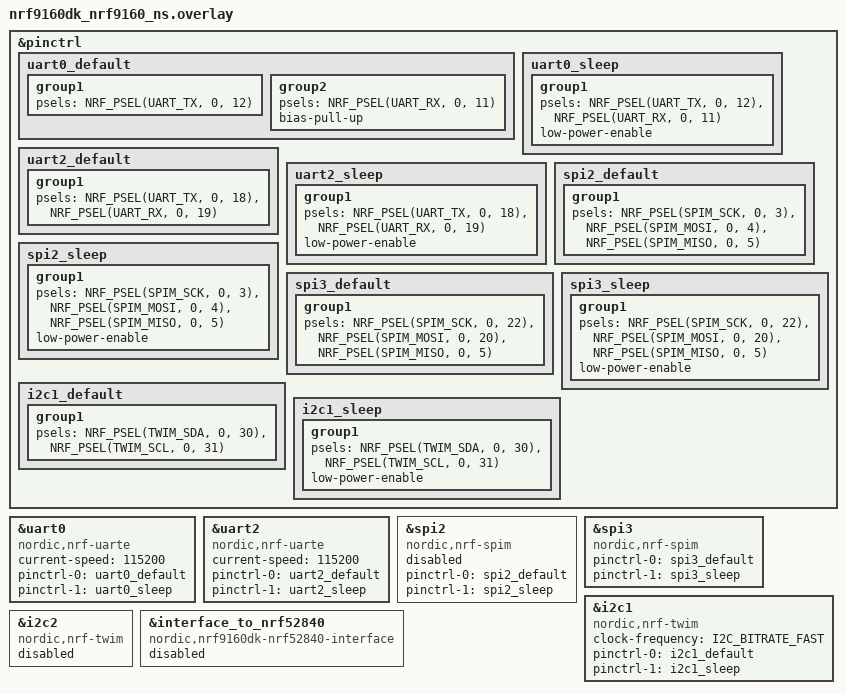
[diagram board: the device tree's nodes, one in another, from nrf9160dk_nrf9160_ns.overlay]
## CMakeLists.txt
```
#
# Copyright (c) 2019 Nordic Semiconductor ASA
#
# SPDX-License-Identifier: LicenseRef-BSD-5-Clause-Nordic
#

cmake_minimum_required(VERSION 3.20.0)

find_package(Zephyr REQUIRED HINTS $ENV{ZEPHYR_BASE})
project(E2)

target_sources(app PRIVATE src/main.c)
target_include_directories(app PRIVATE $ENV{ZEPHYR_BASE}/subsys/fs/nvs)

add_subdirectory(src/datetime)
add_subdirectory(src/font)
add_subdirectory(src/image)
add_subdirectory(src/lcd)
add_subdirectory(src/key)
add_subdirectory(src/settings)
add_subdirectory(src/inner_flash)
add_subdirectory(src/external_flash)
add_subdirectory(src/uart_ble)
add_subdirectory(src/gps)
add_subdirectory(src/nb)
add_subdirectory(src/screen)
add_subdirectory(src/pmu)
add_subdirectory(src/sos)
add_subdirectory(src/codetrans)
add_subdirectory(src/ucs2)
add_subdirectory(src/communicate)
add_subdirectory(src/logger)
#add_subdirectory(src/cryptoauthentication)

add_subdirectory_ifdef(CONFIG_ALARM_SUPPORT src/alarm)
add_subdirectory_ifdef(CONFIG_ANIMATION_SUPPORT src/animation)
add_subdirectory_ifdef(CONFIG_TOUCH_SUPPORT src/tp)
add_subdirectory_ifdef(CONFIG_IMU_SUPPORT src/imu)
add_subdirectory_ifdef(CONFIG_PPG_SUPPORT src/ppg)
add_subdirectory_ifdef(CONFIG_AUDIO_SUPPORT src/audio)
add_subdirectory_ifdef(CONFIG_TEMP_SUPPORT src/temperature)
add_subdirectory_ifdef(CONFIG_CRC_SUPPORT src/crc_check)
add_subdirectory_ifdef(CONFIG_SYNC_SUPPORT src/sync)
add_subdirectory_ifdef(CONFIG_WIFI_SUPPORT src/wifi)
add_subdirectory_ifdef(CONFIG_WATCHDOG src/watchdog)
add_subdirectory_ifdef(CONFIG_FOTA_DOWNLOAD src/fota)
add_subdirectory_ifdef(CONFIG_DATA_DOWNLOAD_SUPPORT src/data_download)
add_subdirectory_ifdef(CONFIG_BARCODE_SUPPORT src/barcode)
add_subdirectory_ifdef(CONFIG_QRCODE_SUPPORT src/qrcode)
add_subdirectory_ifdef(CONFIG_FACTORY_TEST_SUPPORT src/factory_test)
```

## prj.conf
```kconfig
#
# Copyright (c) 2019 Nordic Semiconductor ASA
#
# SPDX-License-Identifier: LicenseRef-BSD-5-Clause-Nordic
#
# General config
CONFIG_NEWLIB_LIBC=y
CONFIG_NEWLIB_LIBC_FLOAT_PRINTF=y
CONFIG_ASSERT=y
CONFIG_REBOOT=y
CONFIG_GPIO=y
CONFIG_TRUSTED_EXECUTION_NONSECURE=y

# Log
CONFIG_LOG=n
CONFIG_USE_SEGGER_RTT=y
CONFIG_LOG_BACKEND_RTT=y
CONFIG_LOG_BACKEND_UART=n
CONFIG_LOG_DEFAULT_LEVEL=4
CONFIG_LOG_MODE_OVERFLOW=y
CONFIG_LOG_BACKEND_RTT_MODE_DROP=y
CONFIG_LOG_BACKEND_SHOW_COLOR=n
CONFIG_LOG_BACKEND_FORMAT_TIMESTAMP=n

# TFM config
#CONFIG_BUILD_WITH_TFM=y
#CONFIG_TFM_PROFILE_TYPE_NOT_SET=y
#CONFIG_TFM_PROFILE_TYPE_MINIMAL=y
#CONFIG_TFM_IPC=n

# PinCtrl
CONFIG_PINCTRL=y
CONFIG_PINCTRL_NRF=y

# watch dog
CONFIG_WATCHDOG=y
CONFIG_WATCHDOG_TIMEOUT_MSEC=10000

# Modem info
CONFIG_MODEM_INFO=y

# Modem library
CONFIG_NRF_MODEM_LIB=y
CONFIG_NRF_MODEM_LIB_SYS_INIT=n

# NVS
CONFIG_FLASH=y
CONFIG_FLASH_PAGE_LAYOUT=y
CONFIG_NVS=y
CONFIG_NVS_LOG_LEVEL_DBG=y
CONFIG_MPU_ALLOW_FLASH_WRITE=y

# GPS
CONFIG_GPS_SUPPORT=y
# Enable to use an external GNSS antenna
CONFIG_GNSS_SAMPLE_ANTENNA_EXTERNAL=y
# Enable to use nRF Cloud A-GPS
CONFIG_GNSS_SAMPLE_ASSISTANCE_NRF_CLOUD=n
# Secure User-Plane Location (SUPL) client library (https://developer.nordicsemi.com/nRF_Connect_SDK/doc/latest/nrf/libraries/others/supl_os_client.html)
CONFIG_GNSS_SAMPLE_ASSISTANCE_SUPL=y

# Console
CONFIG_CONSOLE_SUBSYS=n
CONFIG_CONSOLE_HANDLER=n
CONFIG_CONSOLE_GETCHAR=n
CONFIG_CONSOLE=y
CONFIG_RTT_CONSOLE=y
CONFIG_UART_CONSOLE=n

# Network
CONFIG_NETWORKING=y
CONFIG_NET_NATIVE=n
CONFIG_NET_SOCKETS_OFFLOAD=y
CONFIG_NET_SOCKETS=y
CONFIG_NET_SOCKETS_POSIX_NAMES=y

# Socket
CONFIG_POSIX_MAX_FDS=15
CONFIG_NET_SOCKETS_TLS_MAX_CONTEXTS=5

# LTE link control
CONFIG_LTE_LINK_CONTROL=y
CONFIG_LTE_AUTO_INIT_AND_CONNECT=n
CONFIG_LTE_NETWORK_USE_FALLBACK=n
CONFIG_LTE_NETWORK_TIMEOUT=120
CONFIG_LTE_NETWORK_MODE_LTE_M_GPS=n
CONFIG_LTE_NETWORK_MODE_NBIOT_GPS=y

# PSM
CONFIG_MODEM_AUTO_REQUEST_POWER_SAVING_FEATURES=y
# Set Periodic-TAU timer to 70 mins and Active-Time to 10 seconds.
CONFIG_LTE_PSM_REQ_RPTAU="00000111"
CONFIG_LTE_PSM_REQ_RAT="00000101"

# MQTT
CONFIG_MQTT_LIB=y
CONFIG_MQTT_LIB_TLS=n
CONFIG_MQTT_KEEPALIVE=60
CONFIG_MQTT_PUB_TOPIC="device/e2/pushdata"
CONFIG_MQTT_LOG_PUB_TOPIC="device/e2/pushlog"
CONFIG_MQTT_SUB_TOPIC="device/e2/"
CONFIG_MQTT_CLIENT_ID="my-client-id"
CONFIG_MQTT_USER_NAME="admin123"
CONFIG_MQTT_PASSWORD="admin123"
CONFIG_MQTT_DOMESTIC_BROKER_HOSTNAME="device.audarhealth.cn"
CONFIG_MQTT_DOMESTIC_BROKER_PORT=1883
CONFIG_MQTT_FOREIGN_BROKER_HOSTNAME="device.audarhealth.com"
CONFIG_MQTT_FOREIGN_BROKER_PORT=1883
CONFIG_MQTT_MESSAGE_BUFFER_SIZE=4096
CONFIG_MQTT_PAYLOAD_BUFFER_SIZE=4096

# Library for buttons and LEDs
CONFIG_DK_LIBRARY=y

# Heap and stacks
CONFIG_HEAP_MEM_POOL_SIZE=16384
CONFIG_MAIN_STACK_SIZE=8192
CONFIG_SYSTEM_WORKQUEUE_STACK_SIZE=2048
CONFIG_HW_STACK_PROTECTION=y

# SPI
CONFIG_SPI=y

# I2C
CONFIG_I2C=y

# UART
CONFIG_SERIAL=y
CONFIG_UART_INTERRUPT_DRIVEN=y

# ANIMATION
CONFIG_ANIMATION_SUPPORT=y

# PPG
CONFIG_PPG_SUPPORT=n

# IMU
CONFIG_IMU_SUPPORT=n
CONFIG_STEP_SUPPORT=n
CONFIG_SLEEP_SUPPORT=n
CONFIG_FALL_DETECT_SUPPORT=n

# WIFI
CONFIG_WIFI_SUPPORT=n

# TP
CONFIG_TOUCH_SUPPORT=n

# AUDIO
CONFIG_AUDIO_SUPPORT=n

# BLE
CONFIG_BLE_SUPPORT=n

# Data Sync
CONFIG_SYNC_SUPPORT=y

# Temperature
CONFIG_TEMP_SUPPORT=n

# CRC Check
CONFIG_CRC_SUPPORT=y

# DEVICE POWER MANAGEMENT
CONFIG_PM_DEVICE=y

# Download client
CONFIG_DOWNLOAD_CLIENT=y
CONFIG_DOWNLOAD_CLIENT_MAX_HOSTNAME_SIZE=192
CONFIG_DOWNLOAD_CLIENT_MAX_FILENAME_SIZE=64
CONFIG_DOWNLOAD_CLIENT_STACK_SIZE=4096

# DATA UPDATE
CONFIG_DATA_DOWNLOAD_SUPPORT=y
CONFIG_DATA_DOWNLOAD_HOST_HK="aug-fm-files-hk.oss-cn-hongkong.aliyuncs.com"
CONFIG_DATA_DOWNLOAD_HOST_CN="aug-fm-files-cn.oss-cn-shenzhen.aliyuncs.com"
# IMG
CONFIG_IMG_DATA_UPDATE=y
CONFIG_IMG_DATA_DOWNLOAD_FILE="e2_img.bin"
# FONT
CONFIG_FONT_DATA_UPDATE=y
CONFIG_FONT_DATA_DOWNLOAD_FILE="e2_font.bin"
# PPG
CONFIG_PPG_DATA_UPDATE=y
CONFIG_PPG_DATA_DOWNLOAD_FILE="e2_ppg.bin"

# fota download
CONFIG_FOTA_DOWNLOAD=y
CONFIG_FOTA_DOWNLOAD_PROGRESS_EVT=y
CONFIG_FOTA_DOWNLOAD_HOST_HK="aug-fm-files-hk.oss-cn-hongkong.aliyuncs.com"
CONFIG_FOTA_DOWNLOAD_HOST_CN="aug-fm-files-cn.oss-cn-shenzhen.aliyuncs.com"
CONFIG_FOTA_DOWNLOAD_FILE="e2_update.bin"
# Image manager
CONFIG_IMG_MANAGER=y
#CONFIG_FLASH=y
CONFIG_IMG_ERASE_PROGRESSIVELY=y
# DFU Target
CONFIG_DFU_TARGET=y
# Modem key management
CONFIG_MODEM_KEY_MGMT=y
# Application Upgrade support
CONFIG_BOOTLOADER_MCUBOOT=y

# bar encode
CONFIG_BARCODE_SUPPORT=n

# QR encode
CONFIG_QRCODE_SUPPORT=y

# wrist off check
CONFIG_WRIST_CHECK_SUPPORT=n

# Facotry test
CONFIG_FACTORY_TEST_SUPPORT=n

# Fast Key
CONFIG_FAST_KEY_SUPPORT=y

# Alarm
CONFIG_ALARM_SUPPORT=n

CONFIG_ENTROPY_GENERATOR=y
CONFIG_TEST_RANDOM_GENERATOR=y
```

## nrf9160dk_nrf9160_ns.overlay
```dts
/* SPDX-License-Identifier: Apache-2.0 */

&pinctrl
{
	uart0_default: uart0_default
	{
		group1
		{
			psels = <NRF_PSEL(UART_TX, 0, 12)>;
		};
		group2
		{
			psels = <NRF_PSEL(UART_RX, 0, 11)>;
			bias-pull-up;
		};
	};

	uart0_sleep: uart0_sleep
	{
		group1
		{
			psels = <NRF_PSEL(UART_TX, 0, 12)>,
							<NRF_PSEL(UART_RX, 0, 11)>;
			low-power-enable;
		};
	};
	
	uart2_default: uart2_default
	{
		group1
		{
			psels = <NRF_PSEL(UART_TX, 0, 18)>,
							<NRF_PSEL(UART_RX, 0, 19)>;
		};
	};

	uart2_sleep: uart2_sleep
	{
		group1
		{
			psels = <NRF_PSEL(UART_TX, 0, 18)>,
							<NRF_PSEL(UART_RX, 0, 19)>;
			low-power-enable;
		};
	};
	
	spi2_default: spi2_default
	{
		group1
		{
			psels = <NRF_PSEL(SPIM_SCK,  0, 3)>,
							<NRF_PSEL(SPIM_MOSI, 0, 4)>,
							<NRF_PSEL(SPIM_MISO, 0, 5)>;
		};
	};

	spi2_sleep: spi2_sleep
	{
		group1
		{
			psels = <NRF_PSEL(SPIM_SCK,  0, 3)>,
							<NRF_PSEL(SPIM_MOSI, 0, 4)>,
							<NRF_PSEL(SPIM_MISO, 0, 5)>;
			low-power-enable;
		};
	};
	
	spi3_default: spi3_default
	{
		group1
		{
			psels = <NRF_PSEL(SPIM_SCK,  0, 22)>,
							<NRF_PSEL(SPIM_MOSI, 0, 20)>,
							<NRF_PSEL(SPIM_MISO, 0, 5)>;
		};
	};

	spi3_sleep: spi3_sleep
	{
		group1
		{
			psels = <NRF_PSEL(SPIM_SCK,  0, 22)>,
							<NRF_PSEL(SPIM_MOSI, 0, 20)>,
							<NRF_PSEL(SPIM_MISO, 0, 5)>;
			low-power-enable;
		};
	};
	
	i2c1_default: i2c1_default
	{
		group1
		{
			psels = <NRF_PSEL(TWIM_SDA, 0, 30)>,
							<NRF_PSEL(TWIM_SCL, 0, 31)>;
		};
	};

	i2c1_sleep: i2c1_sleep
	{
		group1
		{
			psels = <NRF_PSEL(TWIM_SDA, 0, 30)>,
							<NRF_PSEL(TWIM_SCL, 0, 31)>;
			low-power-enable;
		};
	};
};


&uart0{
	compatible = "nordic,nrf-uarte";
	status = "okay";
	current-speed = <115200>;
	pinctrl-0 = <&uart0_default>;
	pinctrl-1 = <&uart0_sleep>;
	pinctrl-names = "default", "sleep";
};

&uart2{
	compatible = "nordic,nrf-uarte";
	status = "okay";
	current-speed = <115200>;
	pinctrl-0 = <&uart2_default>;
	pinctrl-1 = <&uart2_sleep>;
	pinctrl-names = "default", "sleep";
};

&spi2{
	compatible = "nordic,nrf-spim";
	status = "disabled";
	pinctrl-0 = <&spi2_default>;
	pinctrl-1 = <&spi2_sleep>;
	pinctrl-names = "default", "sleep";
};

&spi3{
	compatible = "nordic,nrf-spim";
	status = "okay";
	pinctrl-0 = <&spi3_default>;
	pinctrl-1 = <&spi3_sleep>;
	pinctrl-names = "default", "sleep";
};

&i2c1{
	compatible = "nordic,nrf-twim";
	status = "okay";
	clock-frequency = <I2C_BITRATE_FAST>;
	pinctrl-0 = <&i2c1_default>;
	pinctrl-1 = <&i2c1_sleep>;
	pinctrl-names = "default", "sleep";
};

&i2c2{
	compatible = "nordic,nrf-twim";
	status = "disabled";
};

&interface_to_nrf52840{
	compatible = "nordic,nrf9160dk-nrf52840-interface";
	status = "disabled";
};
```

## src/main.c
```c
/*
* Copyright (c) 2019 Nordic Semiconductor ASA
*
* SPDX-License-Identifier: LicenseRef-BSD-5-Clause-Nordic
*/

#include <nrf9160.h>
#include <zephyr/kernel.h>
#include <zephyr/device.h>
#include <stdio.h>
#include <zephyr/sys/printk.h>
#include <power/reboot.h>
#include <zephyr/drivers/spi.h>
#include <zephyr/drivers/gpio.h>
#include <modem/nrf_modem_lib.h>
#include <dk_buttons_and_leds.h>
#include "lcd.h"
#include "datetime.h"
#include "font.h"
#include "img.h"
#include "inner_flash.h"
#include "external_flash.h"
#include "uart_ble.h"
#include "settings.h"
#ifdef CONFIG_TOUCH_SUPPORT
#include "CST816.h"
#endif
#include "Max20353.h"
#ifdef CONFIG_IMU_SUPPORT
#include "lsm6dso.h"
#endif
#ifdef CONFIG_ALARM_SUPPORT
#include "Alarm.h"
#endif
#include "gps.h"
#include "screen.h"
#include "codetrans.h"
#ifdef CONFIG_AUDIO_SUPPORT
#include "audio.h"
#endif
#ifdef CONFIG_WATCHDOG
#include "watchdog.h"
#endif
#ifdef CONFIG_TEMP_SUPPORT
#include "temp.h"
#endif
#ifdef CONFIG_WIFI_SUPPORT
#include "esp8266.h"
#endif/*CONFIG_WIFI_SUPPORT*/
#include "logger.h"

//#define ANALOG_CLOCK
#define DIGITAL_CLOCK
#define PI 3.1415926

static bool sys_pwron_completed_flag = false;
static uint8_t show_pic_count = 0;//图片显示顺序

/* Stack definition for application workqueue */
K_THREAD_STACK_DEFINE(nb_stack_area,
		      4096);
static struct k_work_q nb_work_q;

#ifdef CONFIG_IMU_SUPPORT
K_THREAD_STACK_DEFINE(imu_stack_area,
              2048);
static struct k_work_q imu_work_q;
#endif

K_THREAD_STACK_DEFINE(gps_stack_area,
              2048);
static struct k_work_q gps_work_q;

#if defined(ANALOG_CLOCK)
static void test_show_analog_clock(void);
#elif defined(DIGITAL_CLOCK)
static void test_show_digital_clock(void);
#endif
static void idle_show_time(void);

#ifdef ANALOG_CLOCK
void ClearAnalogHourPic(int hour)
{
	uint16_t offset_x=4,offset_y=4;
	uint16_t hour_x,hour_y,hour_w,hour_h;

	LCD_get_pic_size(clock_hour_1_31X31,&hour_w,&hour_h);
	hour_x = (LCD_WIDTH)/2;
	hour_y = (LCD_HEIGHT)/2;

	if((hour%12) == 3)
		LCD_Fill(hour_x-offset_x,hour_y+offset_y-hour_h,hour_w,hour_h,BLACK);
	else if((hour%12) == 6)
		LCD_Fill(hour_x-offset_x,hour_y-offset_y,hour_w,hour_h,BLACK);
	else if((hour%12) == 9)
		LCD_Fill(hour_x+offset_x-hour_w,hour_y-offset_y,hour_w,hour_h,BLACK);
	else if((hour%12) == 0)
		LCD_Fill(hour_x+offset_x-hour_w,hour_y+offset_y-hour_h,hour_w,hour_h,BLACK);
}

void DrawAnalogHourPic(int hour)
{
	uint16_t offset_x=4,offset_y=4;
	uint16_t hour_x,hour_y,hour_w,hour_h;
	unsigned int *hour_pic[3] = {clock_hour_1_31X31,clock_hour_2_31X31,clock_hour_3_31X31};

	LCD_get_pic_size(clock_hour_1_31X31,&hour_w,&hour_h);
	hour_x = (LCD_WIDTH)/2;
	hour_y = (LCD_HEIGHT)/2;

	if((hour%12)<3)
		LCD_dis_pic_rotate(hour_x-offset_x,hour_y+offset_y-hour_h,hour_pic[hour%3],0);
	else if(((hour%12)>=3) && ((hour%12)<6))
		LCD_dis_pic_rotate(hour_x-offset_x,hour_y-offset_y,hour_pic[hour%3],90);
	else if(((hour%12)>=6) && ((hour%12)<9))
		LCD_dis_pic_rotate(hour_x+offset_x-hour_w,hour_y-offset_y,hour_pic[hour%3],180);
	else if(((hour%12)>=9) && ((hour%12)<12))
		LCD_dis_pic_rotate(hour_x+offset_x-hour_w,hour_y+offset_y-hour_h,hour_pic[hour%3],270);
}

void ClearAnalogMinPic(int minute)
{
	uint16_t offset_x=4,offset_y=4;
	uint16_t min_x,min_y,min_w,min_h;
	
	LCD_get_pic_size(clock_min_1_31X31,&min_w,&min_h);
	min_x = (LCD_WIDTH)/2;
	min_y = (LCD_HEIGHT)/2;

	if(minute == 15)
		LCD_Fill(min_x-offset_x,min_y+offset_y-min_h,min_w,min_h,BLACK);
	else if(minute == 30)
		LCD_Fill(min_x-offset_x,min_y-offset_y,min_w,min_h,BLACK);
	else if(minute == 45)
		LCD_Fill(min_x+offset_x-min_w,min_y-offset_y,min_w,min_h,BLACK);
	else if(minute == 0)
		LCD_Fill(min_x+offset_x-min_w,min_y+offset_y-min_h,min_w,min_h,BLACK);
}

void DrawAnalogMinPic(int hour, int minute)
{
	uint16_t offset_x=4,offset_y=4;
	uint16_t min_x,min_y,min_w,min_h;
	unsigned int *min_pic[15] = {clock_min_1_31X31,clock_min_2_31X31,clock_min_3_31X31,clock_min_4_31X31,clock_min_5_31X31,\
								 clock_min_6_31X31,clock_min_7_31X31,clock_min_8_31X31,clock_min_9_31X31,clock_min_10_31X31,\
								 clock_min_11_31X31,clock_min_12_31X31,clock_min_13_31X31,clock_min_14_31X31,clock_min_15_31X31};
	
	LCD_get_pic_size(clock_min_1_31X31,&min_w,&min_h);
	min_x = (LCD_WIDTH)/2;
	min_y = (LCD_HEIGHT)/2;

	if(minute<15)
	{
		if((hour%12)<3)							//分针时针有重叠，透明显示
		{
			DrawAnalogHourPic(hour);
			LCD_dis_pic_trans_rotate(min_x-offset_x,min_y+offset_y-min_h,min_pic[minute%15],BLACK,0);
		}
		else if((hour%12)==3)		//临界点，分针不透明显示，但是不能遮盖时针
		{
			LCD_dis_pic_rotate(min_x-offset_x,min_y+offset_y-min_h,min_pic[minute%15],0);
			DrawAnalogHourPic(hour);
		}
		else
			LCD_dis_pic_rotate(min_x-offset_x,min_y+offset_y-min_h,min_pic[minute%15],0);
	}
	else if((minute>=15) && (minute<30))
	{
		if(((hour%12)>=3) && ((hour%12)<6))	//分针时针有重叠，透明显示
		{
			DrawAnalogHourPic(hour);
			LCD_dis_pic_trans_rotate(min_x-offset_x,min_y-offset_y,min_pic[minute%15],BLACK,90);
		}
		else if((hour%12)==6)		//临界点，分针不透明显示，但是不能遮盖时针
		{
			LCD_dis_pic_rotate(min_x-offset_x,min_y-offset_y,min_pic[minute%15],90);
			DrawAnalogHourPic(hour);
		}
		else
			LCD_dis_pic_rotate(min_x-offset_x,min_y-offset_y,min_pic[minute%15],90);
	}
	else if((minute>=30) && (minute<45))
	{
		if(((hour%12)>=6) && ((hour%12)<9))	//分针时针有重叠，透明显示
		{
			DrawAnalogHourPic(hour);
			LCD_dis_pic_trans_rotate(min_x+offset_x-min_w,min_y-offset_y,min_pic[minute%15],BLACK,180);
		}
		else if((hour%12)==9)		//临界点，分针不透明显示，但是不能遮盖时针
		{
			LCD_dis_pic_rotate(min_x+offset_x-min_w,min_y-offset_y,min_pic[minute%15],180);
			DrawAnalogHourPic(hour);
		}
		else
			LCD_dis_pic_rotate(min_x+offset_x-min_w,min_y-offset_y,min_pic[minute%15],180);
	}
	else if((minute>=45) && (minute<60))
	{
		if((hour%12)>=9)	//分针时针有重叠，透明显示
		{
			DrawAnalogHourPic(hour);
			LCD_dis_pic_trans_rotate(min_x+offset_x-min_w,min_y+offset_y-min_h,min_pic[minute%15],BLACK,270);
		}
		else if((hour%12)==0)		//临界点，分针不透明显示，但是不能遮盖时针
		{
			LCD_dis_pic_rotate(min_x+offset_x-min_w,min_y+offset_y-min_h,min_pic[minute%15],270);
			DrawAnalogHourPic(hour);
		}
		else
			LCD_dis_pic_rotate(min_x+offset_x-min_w,min_y+offset_y-min_h,min_pic[minute%15],270);
	}
}
#endif

/***************************************************************************
* 描  述 : idle_show_digit_clock 待机界面显示数字时钟
* 入  参 : 无 
* 返回值 : 无
**************************************************************************/
void idle_show_digital_clock(void)
{
	IdleShowSystemTime();
	
	if(show_date_time_first || ((date_time_changed&0x38) != 0))
	{
		IdleShowSystemDate();
		IdleShowSystemWeek();

		if(show_date_time_first)
			show_date_time_first = false;
		if((date_time_changed&0x38) != 0)
			date_time_changed = date_time_changed&0xC7;//清空日期变化标志位
	}
}

#ifdef ANALOG_CLOCK
/***************************************************************************
* 描  述 : idle_show_analog_clock 待机界面显示模拟时钟
* 入  参 : 无 
* 返回值 : 无
**************************************************************************/
void idle_show_analog_clock(void)
{
	uint8_t str_date[20] = {0};
	uint8_t str_week[20] = {0};
	uint8_t *week_cn[7] = {"周日", "周一", "周二", "周三", "周四", "周五", "周六"};
	uint8_t *week_en[7] = {"SUN", "MON", "TUE", "WED", "THU", "FRI", "SAT"};
	uint16_t str_w,str_h;

	POINT_COLOR=WHITE;								//画笔颜色
	BACK_COLOR=BLACK;  								//背景色 

#ifdef FONTMAKER_UNICODE_FONT
	LCD_SetFontSize(FONT_SIZE_20);
#else
	LCD_SetFontSize(FONT_SIZE_16);
#endif

	sprintf((char*)str_date, "%02d/%02d", date_time.day,date_time.month);
	if(global_settings.language == LANGUAGE_CHN)
		strcpy(str_week, week_cn[date_time.week]);
	else
		strcpy(str_week, week_en[date_time.week]);
	
	if(show_date_time_first)
	{
		show_date_time_first = false;
		DrawAnalogHourPic(date_time.hour);
		DrawAnalogMinPic(date_time.hour, date_time.minute);

		LCD_MeasureString(str_week, &str_w, &str_h);
		LCD_ShowString((LCD_WIDTH-str_w)/2, 15, str_week);

		LCD_MeasureString(str_date, &str_w, &str_h);
		LCD_ShowString((LCD_WIDTH-str_w)/2, 33, str_date);
	}
	else if(date_time_changed != 0)
	{
		if((date_time_changed&0x04) != 0)
		{
			DrawAnalogHourPic(date_time.hour);
			date_time_changed = date_time_changed&0xFB;
		}	
		if((date_time_changed&0x02) != 0)//分钟有变化
		{
			DrawAnalogHourPic(date_time.hour);
			DrawAnalogMinPic(date_time.hour, date_time.minute);
			date_time_changed = date_time_changed&0xFD;
		}
		if((date_time_changed&0x38) != 0)
		{
			LCD_MeasureString(str_week, &str_w, &str_h);
			LCD_ShowString((LCD_WIDTH-str_w)/2, 15, str_week);

			LCD_MeasureString(str_date, &str_w, &str_h);
			LCD_ShowString((LCD_WIDTH-str_w)/2, 33, str_date);

			date_time_changed = date_time_changed&0xC7;//清空日期变化标志位
		}
	}
}
#endif

void idle_show_clock_background(void)
{
	LCD_Clear(BLACK);
	BACK_COLOR=BLACK;
	POINT_COLOR=WHITE;

#ifdef FONTMAKER_UNICODE_FONT
	LCD_SetFontSize(FONT_SIZE_20);
#else	
	LCD_SetFontSize(FONT_SIZE_16);
#endif

#ifdef ANALOG_CLOCK	
	if(global_settings.idle_colck_mode == CLOCK_MODE_ANALOG)
	{
		LCD_dis_pic(0,0,clock_bg_80X160);
	}
#endif
}

/***************************************************************************
* 描  述 : idle_show_time 待机界面显示时间
* 入  参 : 无 
* 返回值 : 无
**************************************************************************/
void idle_show_time(void)
{	
	if(global_settings.idle_colck_mode == CLOCK_MODE_ANALOG)
	{
	#ifdef ANALOG_CLOCK
		if((date_time_changed&0x02) != 0)
		{
			ClearAnalogMinPic(date_time.minute);//擦除以前的分钟
		}
		if((date_time_changed&0x04) != 0)
		{
			ClearAnalogHourPic(date_time.hour);//擦除以前的时钟
		}

		idle_show_analog_clock();
	#endif
	}
	else
	{
	#ifdef DIGITAL_CLOCK
		if((date_time_changed&0x01) != 0)
		{
			date_time_changed = date_time_changed&0xFE;
			BlockWrite((LCD_WIDTH-8*8)/2+6*8,(LCD_HEIGHT-16)/2,2*8,16);//擦除以前的秒钟
		}
		if((date_time_changed&0x02) != 0)
		{
			date_time_changed = date_time_changed&0xFD;
			BlockWrite((LCD_WIDTH-8*8)/2+3*8,(LCD_HEIGHT-16)/2,2*8,16);//擦除以前的分钟
		}
		if((date_time_changed&0x04) != 0)
		{
			date_time_changed = date_time_changed&0xFB;
			BlockWrite((LCD_WIDTH-8*8)/2,(LCD_HEIGHT-16)/2,2*8,16);//擦除以前的时钟
		}
		
		if((date_time_changed&0x38) != 0)
		{			
			BlockWrite((LCD_WIDTH-10*8)/2,(LCD_HEIGHT-16)/2+30,10*8,16);
		}
		
		idle_show_digital_clock();
	#endif
	}
}

void test_show_analog_clock(void)
{
	uint32_t err_code;
	
	global_settings.idle_colck_mode = CLOCK_MODE_ANALOG;
	
	idle_show_clock_background();
	idle_show_time();
}

void test_show_digital_clock(void)
{
	uint32_t err_code;
	
	global_settings.idle_colck_mode == CLOCK_MODE_DIGITAL;
	
	idle_show_clock_background();
	idle_show_time();
}

void test_show_image(void)
{
	uint8_t i=0;
	uint16_t x,y,w=0,h=0;
	
	LCD_Clear(BLACK);

#ifdef LCD_VG6432TSWPG28_SSD1315
	LCD_ShowImg(0, 0, gImage_jjph_gc_64x32);
#endif
	k_sleep(K_MSEC(2000));

	//LCD_get_pic_size(peppa_pig_160X160, &w, &h);
	//LCD_dis_pic_rotate(0,200,peppa_pig_160X160,270);
	//LCD_dis_pic(0, 0, peppa_pig_160X160);
	//LCD_get_pic_size_from_flash(IMG_STEP_UNIT_CN_ICON_ADDR, &w, &h);
	//LCD_dis_pic_from_flash((LCD_WIDTH-w)/2, (LCD_HEIGHT-h)/2, IMG_STEP_UNIT_CN_ICON_ADDR);
	//LCD_dis_pic_rotate_from_flash((LCD_WIDTH-w)/2, (LCD_HEIGHT-h)/2, IMG_ANALOG_CLOCK_HAND_HOUR_ADDR, 270);
	//LCD_dis_pic_angle_from_flash(0, 0, IMG_ANALOG_CLOCK_HAND_SEC_ADDR, 360);
	while(1)
	{
	#if 1	
		switch(i)
		{
			case 0:
				LCD_ShowImg(0, 0, gImage_IDLE_1);
				//LCD_dis_pic(w*0,h*0,peppa_pig_160X160);
				//LCD_dis_pic_trans(w*0,h*0,peppa_pig_80X160,WHITE);
				//LCD_dis_pic_from_flash(w*0, h*0, IMG_ANALOG_CLOCK_BG_ADDR);
				//LCD_dis_pic_rotate((LCD_WIDTH-w)/2,(LCD_HEIGHT-h)/2,peppa_pig_160X160,0);
				//LCD_dis_pic_trans_rotate((LCD_WIDTH-w)/2,(LCD_HEIGHT-h)/2,peppa_pig_160X160,WHITE,0);
				break;
			case 1:
				LCD_ShowImg(0, 0, gImage_IDLE_2);
				//LCD_dis_pic(w*1,h*0,peppa_pig_160X160);
				//LCD_dis_pic_trans(w*1,h*0,peppa_pig_80X160,WHITE);
				//LCD_dis_pic_from_flash(w*1, h*0, IMG_ANALOG_CLOCK_BG_ADDR);
				//LCD_dis_pic_rotate((LCD_WIDTH-w)/2,(LCD_HEIGHT-h)/2,peppa_pig_160X160,90);
				//LCD_dis_pic_trans_rotate((LCD_WIDTH-w)/2,(LCD_HEIGHT-h)/2,peppa_pig_160X160,WHITE,90);
				break;
			case 2:
				LCD_ShowImg(0, 0, gImage_IDLE_3);
				//LCD_dis_pic(w*1,h*1,peppa_pig_160X160);
				//LCD_dis_pic_trans(w*1,h*1,peppa_pig_80X160,WHITE);
				//LCD_dis_pic_from_flash(w*1, h*1, IMG_ANALOG_CLOCK_BG_ADDR);
				//LCD_dis_pic_rotate((LCD_WIDTH-w)/2,(LCD_HEIGHT-h)/2,peppa_pig_160X160,180);
				//LCD_dis_pic_trans_rotate((LCD_WIDTH-w)/2,(LCD_HEIGHT-h)/2,peppa_pig_160X160,WHITE,180);
				break;
			case 3:
				LCD_ShowImg(0, 0, gImage_IDLE_4);
				//LCD_dis_pic(w*0,h*1,peppa_pig_160X160);
				//LCD_dis_pic_trans(w*0,h*1,peppa_pig_80X160,WHITE);
				//LCD_dis_pic_from_flash(w*0, h*1, IMG_ANALOG_CLOCK_BG_ADDR);
				//LCD_dis_pic_rotate((LCD_WIDTH-w)/2,(LCD_HEIGHT-h)/2,peppa_pig_160X160,270);
				//LCD_dis_pic_trans_rotate((LCD_WIDTH-w)/2,(LCD_HEIGHT-h)/2,peppa_pig_160X160,WHITE,270);
				break;
			case 4:
				LCD_ShowImg(0, 0, gImage_IDLE_5);
				//LCD_Fill(w*0,h*0,w,h,BLACK);
				break;
			case 5:
				LCD_ShowImg(0, 0, gImage_IDLE_6);
				//LCD_Fill(w*1,h*0,w,h,BLACK);
				break;
			case 6:
				LCD_ShowImg(0, 0, gImage_IDLE_7);
				//LCD_Fill(w*1,h*1,w,h,BLACK);
				break;
			case 7:
				LCD_Fill(w*0,h*1,w,h,BLACK);
				break;
		}
	#endif

		i++;
		if(i==7)
			i = 0;
		
		k_sleep(K_MSEC(2000));								//软件延时1000ms
	}
}

void test_show_stripe(void)
{
	uint16_t x,y,w,h;
	uint8_t i;
	uint16_t color[] = {WHITE,BLACK,RED,GREEN,BLUE,GBLUE,MAGENTA,CYAN,YELLOW,BROWN,BRRED,GRAY};
	
	h = LCD_HEIGHT/8;

	for(i=0;i<8;i++)
	{
		LCD_Fill(0, h*i, LCD_WIDTH, h, color[i%5]);
	}
}

void test_show_color(void)
{
	uint8_t i=0;

	LOGD("test_show_color");
	
	while(1)
	{
		switch(i)
		{
			case 0:
				LCD_Clear(WHITE);
				break;
			case 1:
				LCD_Clear(BLACK);
				break;
			case 2:
				LCD_Clear(RED);
				break;
			case 3:
				LCD_Clear(GREEN);
				break;
			case 4:
				LCD_Clear(BLUE);
				break;
			case 5:
				LCD_Clear(YELLOW);
				break;
			case 6:
				LCD_Clear(GBLUE);
				break;
			case 7:
				LCD_Clear(MAGENTA);
				break;
			case 8:
				LCD_Clear(CYAN);
				break;
			case 9:
				LCD_Clear(BROWN);
				break;
			case 10:
				LCD_Clear(BRRED);
				break;
			case 11:
				LCD_Clear(GRAY);
				break;					
		}
		
		i++;
		if(i>=12)
			i=0;
		
		k_sleep(K_MSEC(1000));								//软件延时1000ms
	}
}

void test_show_string(void)
{
	uint16_t x,y,w,h;
	uint8_t tmpbuf[256] = {0};
	uint8_t enbuf[64] = {0};
	uint8_t cnbuf[64] = {0};
	uint8_t jpbuf[64] = {0};
	uint16_t en_unibuf[64] = {0x0041,0x0075,0x0067,0x0075,0x0073,0x0074,0x0020,0x0053,0x0068,0x0065,0x006E,0x007A,0x0068,0x0065,0x006E,0x0020,0x0044,0x0049,0x0067,0x0049,0x0074,0x0061,0x006C,0x0020,0x004C,0x0074,0x0064,0x0000};
	uint16_t cn_unibuf[64] = {0x6DF1,0x5733,0x5E02,0x5965,0x79D1,0x65AF,0x6570,0x7801,0x6709,0x9650,0x516C,0x53F8,0x0000};
	uint16_t jp_unibuf[64] = {0x6DF1,0x30BB,0x30F3,0x5E02,0x30AA,0x30FC,0x30B3,0x30B9,0x30C7,0x30B8,0x30BF,0x30EB,0x6709,0x9650,0x4F1A,0x793E,0x0000};

	LCD_Clear(BLACK);
	
	POINT_COLOR=WHITE;								//画笔颜色
	BACK_COLOR=BLACK;  								//背景色 

	LCD_SetFontSize(FONT_SIZE_20);
	LCD_Fill((LCD_WIDTH-180)/2, 60, 180, 100, BLACK);
 	mmi_asc_to_ucs2(tmpbuf, " G:153853,160004\nIR:401502,403683\n R:425776,428105\nhr:0 spo2:0");
 	LCD_ShowUniStringInRect((LCD_WIDTH-180)/2, 60, 180, 100, (uint16_t*)tmpbuf);

	return;

#ifdef FONTMAKER_UNICODE_FONT
#if 0//def FONT_64
	LCD_SetFontSize(FONT_SIZE_64);					//设置字体大小
#elif 0//defined(FONT_48)
	LCD_SetFontSize(FONT_SIZE_48);					//设置字体大小
#elif 0//defined(FONT_32)
	LCD_SetFontSize(FONT_SIZE_32);					//设置字体大小	
#elif 0//defined(FONT_24)
	LCD_SetFontSize(FONT_SIZE_24);					//设置字体大小
#elif defined(FONT_16)
	LCD_SetFontSize(FONT_SIZE_16);					//设置字体大小
#endif
	LCD_MeasureUniString(en_unibuf,&w,&h);
	x = (w > LCD_WIDTH)? 0 : (LCD_WIDTH-w)/2;
	y = 30;	
	LCD_ShowUniString(x,y,en_unibuf);

	LCD_MeasureUniString(cn_unibuf,&w,&h);
	x = (w > LCD_WIDTH)? 0 : (LCD_WIDTH-w)/2;
	y = y + h + 2;
	LCD_ShowUniString(x,y,cn_unibuf);

	LCD_MeasureUniString(jp_unibuf,&w,&h);
	x = (w > LCD_WIDTH)? 0 : (LCD_WIDTH-w)/2;
	y = y + h + 2;
	LCD_ShowUniString(x,y,jp_unibuf);

#if 0
#ifdef FONT_24
	LCD_SetFontSize(FONT_SIZE_24);					//设置字体大小
#endif
	LCD_MeasureUniString(cn_unibuf,&w,&h);
	x = (w > LCD_WIDTH)? 0 : (LCD_WIDTH-w)/2;
	y = y + h + 2;	
	LCD_ShowUniString(x,y,cn_unibuf);
	
	LCD_MeasureUniString(en_unibuf,&w,&h);
	x = (w > LCD_WIDTH)? 0 : (LCD_WIDTH-w)/2;
	y = y + h + 2;	
	LCD_ShowUniString(x,y,en_unibuf);

#ifdef FONT_32
	LCD_SetFontSize(FONT_SIZE_32);					//设置字体大小
#endif
	LCD_MeasureUniString(cn_unibuf,&w,&h);
	x = (w > LCD_WIDTH)? 0 : (LCD_WIDTH-w)/2;
	y = y + h + 2;	
	LCD_ShowUniString(x,y,cn_unibuf);
	
	LCD_MeasureUniString(en_unibuf,&w,&h);
	x = (w > LCD_WIDTH)? 0 : (LCD_WIDTH-w)/2;
	y = y + h + 2;
	LCD_ShowUniString(x,y,en_unibuf);
#endif
#else
	strcpy(enbuf, "August Shenzhen Digital Ltd");
	strcpy(cnbuf, "深圳市奥科斯数码有限公司");
	strcpy(jpbuf, "深セン市オーコスデジタル有限会社");

#ifdef FONT_32
	LCD_SetFontSize(FONT_SIZE_32);					//设置字体大小	
#elif defined(FONT_24)
	LCD_SetFontSize(FONT_SIZE_24);					//设置字体大小
#elif defined(FONT_16)
	LCD_SetFontSize(FONT_SIZE_16);					//设置字体大小
#endif

	LCD_MeasureString(enbuf,&w,&h);
	x = (w > LCD_WIDTH)? 0 : (LCD_WIDTH-w)/2;
	y = y + h + 2;	
	LCD_ShowString(x,y,enbuf);
	
	LCD_MeasureString(cnbuf,&w,&h);
	x = (w > LCD_WIDTH)? 0 : (LCD_WIDTH-w)/2;
	y = y + h + 2;
	LCD_ShowString(x,y,cnbuf);
	
	LCD_MeasureString(jpbuf,&w,&h);
	x = (w > LCD_WIDTH)? 0 : (LCD_WIDTH-w)/2;
	y = y + h + 2;
	LCD_ShowString(x,y,jpbuf);

#if 0
#ifdef FONT_24
	LCD_SetFontSize(FONT_SIZE_24);					//设置字体大小
#endif
	LCD_MeasureString(cnbuf,&w,&h);
	x = (w > LCD_WIDTH)? 0 : (LCD_WIDTH-w)/2;
	y = y + h + 2;	
	LCD_ShowString(x,y,cnbuf);
	
	LCD_MeasureString(enbuf,&w,&h);
	x = (w > LCD_WIDTH)? 0 : (LCD_WIDTH-w)/2;
	y = y + h + 2;	
	LCD_ShowString(x,y,enbuf);

#ifdef FONT_32
	LCD_SetFontSize(FONT_SIZE_32);					//设置字体大小
#endif
	LCD_MeasureString(cnbuf,&w,&h);
	x = (w > LCD_WIDTH)? 0 : (LCD_WIDTH-w)/2;
	y = y + h + 2;	
	LCD_ShowString(x,y,cnbuf);
	
	LCD_MeasureString(enbuf,&w,&h);
	x = (w > LCD_WIDTH)? 0 : (LCD_WIDTH-w)/2;
	y = y + h + 2;
	LCD_ShowString(x,y,enbuf);
#endif
#endif
}

void test_notify(void)
{
	notify_infor infor = {0};
	uint16_t str_note[LANGUAGE_MAX][80] = {
											{0x0054,0x0068,0x0065,0x0020,0x0074,0x0069,0x006D,0x0069,0x006E,0x0067,0x0020,0x006D,0x0065,0x0061,0x0073,0x0075,0x0072,0x0065,0x006D,0x0065,0x006E,0x0074,0x0020,0x0069,0x0073,0x0020,0x0061,0x0062,0x006F,0x0075,0x0074,0x0020,0x0074,0x006F,0x0020,0x0073,0x0074,0x0061,0x0072,0x0074,0x002C,0x0020,0x0061,0x006E,0x0064,0x0020,0x0074,0x0068,0x0069,0x0073,0x0020,0x006D,0x0065,0x0061,0x0073,0x0075,0x0072,0x0065,0x006D,0x0065,0x006E,0x0074,0x0020,0x0069,0x0073,0x0020,0x006F,0x0076,0x0065,0x0072,0x0021,0x0000},//The timing measurement is about to start, and this measurement is over!
											{0x0044,0x0069,0x0065,0x0020,0x005A,0x0065,0x0069,0x0074,0x006D,0x0065,0x0073,0x0073,0x0075,0x006E,0x0067,0x0020,0x0073,0x0074,0x0065,0x0068,0x0074,0x0020,0x006B,0x0075,0x0072,0x007A,0x0020,0x0062,0x0065,0x0076,0x006F,0x0072,0x002C,0x0020,0x0075,0x006E,0x0064,0x0020,0x0064,0x0069,0x0065,0x0073,0x0065,0x0020,0x004D,0x0065,0x0073,0x0073,0x0075,0x006E,0x0067,0x0020,0x0069,0x0073,0x0074,0x0020,0x0076,0x006F,0x0072,0x0062,0x0065,0x0069,0x0021,0x0000},//Die Zeitmessung steht kurz bevor, und diese Messung ist vorbei!
											{0x5B9A,0x65F6,0x6D4B,0x91CF,0x5373,0x5C06,0x5F00,0x59CB,0xFF0C,0x672C,0x6B21,0x6D4B,0x91CF,0x7ED3,0x675F,0xFF01,0x0000},//定时测量即将开始，本次测量结束！
										};

#ifdef FONTMAKER_UNICODE_FONT
	LCD_SetFontSize(FONT_SIZE_20);
#else		
	LCD_SetFontSize(FONT_SIZE_16);
#endif
	
	infor.x = 0;
	infor.y = 0;
	infor.w = LCD_WIDTH;
	infor.h = LCD_HEIGHT;

	infor.align = NOTIFY_ALIGN_CENTER;
	infor.type = NOTIFY_TYPE_POPUP;

	infor.img_count = 0;
	mmi_ucs2cpy(infor.text, (uint8_t*)str_note[0]);

	DisplayPopUp(infor);
}

static void modem_init(void)
{
	nrf_modem_lib_init(NORMAL_MODE);
	boot_write_img_confirmed();
}

void system_init(void)
{
	k_sleep(K_MSEC(500));//xb test 2022-03-11 启动时候延迟0.5S,等待其他外设完全启动

	modem_init();

#ifdef CONFIG_FOTA_DOWNLOAD
	fota_init();
#endif

	InitSystemSettings();

#ifdef CONFIG_IMU_SUPPORT
	init_imu_int1();//xb add 2022-05-27
#endif
#ifdef CONFIG_PPG_SUPPORT
	PPG_i2c_off();
#endif
	pmu_init();
	key_init();
	LCD_Init();
	flash_init();
	
	//ShowBootUpLogo();
	
#ifdef CONFIG_PPG_SUPPORT	
	PPG_init();
#endif
#ifdef CONFIG_AUDIO_SUPPORT	
	audio_init();
#endif
	ble_init();
#ifdef CONFIG_WIFI_SUPPORT
	wifi_init();
#endif
#ifdef CONFIG_IMU_SUPPORT
	IMU_init(&imu_work_q);
#endif
#ifdef CONFIG_TEMP_SUPPORT
	temp_init();
#endif
#ifdef CONFIG_DATA_DOWNLOAD_SUPPORT
	dl_init();
#endif
	LogInit();

	//NB_init(&nb_work_q);
	//GPS_init(&gps_work_q);
}

void work_init(void)
{
	k_work_queue_start(&nb_work_q, nb_stack_area,
					K_THREAD_STACK_SIZEOF(nb_stack_area),
					CONFIG_APPLICATION_WORKQUEUE_PRIORITY,NULL);
#ifdef CONFIG_IMU_SUPPORT	
	k_work_queue_start(&imu_work_q, imu_stack_area,
					K_THREAD_STACK_SIZEOF(imu_stack_area),
					CONFIG_APPLICATION_WORKQUEUE_PRIORITY,NULL);
#endif
	k_work_queue_start(&gps_work_q, gps_stack_area,
					K_THREAD_STACK_SIZEOF(gps_stack_area),
					CONFIG_APPLICATION_WORKQUEUE_PRIORITY,NULL);	
	
	if(IS_ENABLED(CONFIG_WATCHDOG))
	{
		watchdog_init_and_start(&k_sys_work_q);
	}
}

bool system_is_completed(void)
{
	return sys_pwron_completed_flag;
}

void system_init_completed(void)
{
	if(!sys_pwron_completed_flag)
		sys_pwron_completed_flag = true;
}

/***************************************************************************
* 描  述 : main函数 
* 入  参 : 无 
* 返回值 : int 类型
**************************************************************************/
int main(void)
{
	work_init();
	system_init();

//	test_show_string();
	test_show_image();
//	test_show_color();
//	test_show_stripe();
//	test_nvs();
//	test_flash();
//	test_uart_ble();
//	test_sensor();
//	test_show_digital_clock();
//	test_sensor();
//	test_pmu();
//	test_crypto();
//	test_imei_for_qr();
//	test_tp();
//	test_gps_on();
//	test_nb();
//	test_i2c();
//	test_bat_soc();
//	test_notify();
//	test_wifi();
//	LogInit();

	while(0)
	{
		KeyMsgProcess();
		TimeMsgProcess();
		NBMsgProcess();
		GPSMsgProcess();
		PMUMsgProcess();
	#ifdef CONFIG_IMU_SUPPORT	
		IMUMsgProcess();
	#ifdef CONFIG_FALL_DETECT_SUPPORT
		FallMsgProcess();
	#endif
	#endif
	#ifdef CONFIG_PPG_SUPPORT	
		PPGMsgProcess();
	#endif
		LCDMsgProcess();
	#ifdef CONFIG_TOUCH_SUPPORT
		TPMsgProcess();
	#endif
	#ifdef CONFIG_ALARM_SUPPORT
		AlarmMsgProcess();
	#endif
		SettingsMsgPorcess();
		SOSMsgProc();
	#ifdef CONFIG_WIFI_SUPPORT
		WifiMsgProcess();
	#endif
		UartMsgProc();
	#ifdef CONFIG_ANIMATION_SUPPORT
		AnimaMsgProcess();
	#endif		
		ScreenMsgProcess();
	#ifdef CONFIG_DATA_DOWNLOAD_SUPPORT
		DlMsgProc();
	#endif
	#ifdef CONFIG_FOTA_DOWNLOAD
		VerCheckMsgProc();
		FotaMsgProc();
	#endif
	#ifdef CONFIG_AUDIO_SUPPORT
		AudioMsgProcess();
	#endif
	#ifdef CONFIG_SYNC_SUPPORT
		SyncMsgProcess();
	#endif
	#ifdef CONFIG_TEMP_SUPPORT
		TempMsgProcess();
	#endif
	#ifdef CONFIG_FACTORY_TEST_SUPPORT
		FactoryTestProccess();
	#endif
		LogMsgProcess();
		system_init_completed();
		k_cpu_idle();
	}
}
```
